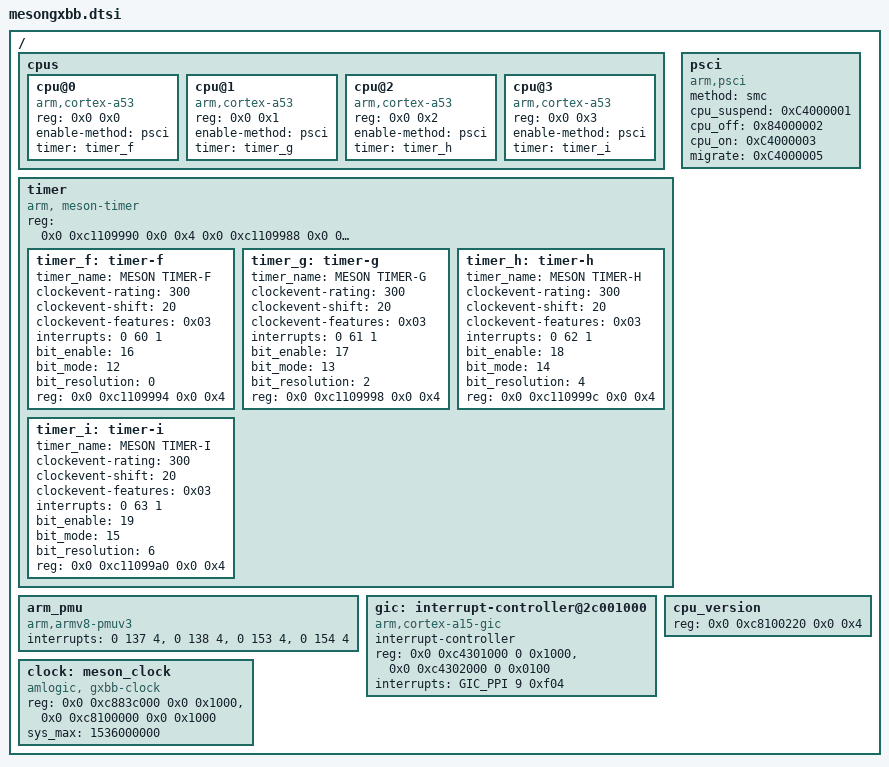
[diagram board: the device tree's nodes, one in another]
#include <dt-bindings/clock/gxbb.h>
/ {
	cpus {
		#address-cells = <2>;
		#size-cells = <0>;

		cpu@0 {
			device_type = "cpu";
			compatible = "arm,cortex-a53","arm,armv8";
			reg = <0x0 0x0>;
			enable-method = "psci";
			timer=<&timer_f>;
		};

		cpu@1 {
			device_type = "cpu";
			compatible = "arm,cortex-a53","arm,armv8";
			reg = <0x0 0x1>;
			enable-method = "psci";
			timer=<&timer_g>;
		};
		cpu@2 {
			device_type = "cpu";
			compatible = "arm,cortex-a53","arm,armv8";
			reg = <0x0 0x2>;
			enable-method = "psci";
			timer=<&timer_h>;
		};

		cpu@3 {
			device_type = "cpu";
			compatible = "arm,cortex-a53","arm,armv8";
			reg = <0x0 0x3>;
			enable-method = "psci";
			timer=<&timer_i>;
		};


	};

	timer{
		compatible = "arm, meson-timer";
		#address-cells = <2>;
		#size-cells = <2>;
		ranges;
		reg=   <0x0 0xc1109990 0x0 0x4 0x0 0xc1109988 0x0 0x4>;
		timer_f:timer-f{
			timer_name="MESON TIMER-F";
			clockevent-rating=<300>;
			clockevent-shift=<20>;
			clockevent-features=<0x03>;
			interrupts = <0 60 1>;
			bit_enable=<16>;
			bit_mode=<12>;
			bit_resolution=<0>;
			reg=   <0x0 0xc1109994 0x0 0x4>;
		};
		timer_g:timer-g{
			timer_name="MESON TIMER-G";
			clockevent-rating=<300>;
			clockevent-shift=<20>;
			clockevent-features=<0x03>;
			interrupts = <0 61 1>;
			bit_enable=<17>;
			bit_mode=<13>;
			bit_resolution=<2>;
			reg=<0x0 0xc1109998 0x0 0x4>;
		};
		timer_h:timer-h{
			timer_name="MESON TIMER-H";
			clockevent-rating=<300>;
			clockevent-shift=<20>;
			clockevent-features=<0x03>;
			interrupts = <0 62 1>;
			bit_enable=<18>;
			bit_mode=<14>;
			bit_resolution=<4>;
			reg=<0x0 0xc110999c 0x0 0x4>;
		};
		timer_i:timer-i{
			timer_name="MESON TIMER-I";
			clockevent-rating=<300>;
			clockevent-shift=<20>;
			clockevent-features=<0x03>;
			interrupts = <0 63 1>;
			bit_enable=<19>;
			bit_mode=<15>;
			bit_resolution=<6>;
			reg=<0x0 0xc11099a0 0x0 0x4>;
		};
	};
	arm_pmu {
		compatible = "arm,armv8-pmuv3";
		interrupts = <0 137 4>,
			     <0 138 4>,
			     <0 153 4>,
			     <0 154 4>;
	};

	gic: interrupt-controller@2c001000 {
		compatible = "arm,cortex-a15-gic", "arm,cortex-a9-gic";
		#interrupt-cells = <3>;
		#address-cells = <0>;
		interrupt-controller;
		reg = <0x0 0xc4301000 0 0x1000>,
		      <0x0 0xc4302000 0 0x0100>;
		interrupts = <GIC_PPI 9 0xf04>;
	};

	psci {
		compatible = "arm,psci";
		method = "smc";
		cpu_suspend = <0xC4000001>;
		cpu_off = <0x84000002>;
		cpu_on = <0xC4000003>;
		migrate = <0xC4000005>;
	};

	clock: meson_clock {
		compatible = "amlogic, gxbb-clock";
		reg = <0x0 0xc883c000 0x0 0x1000>,   /* HIU BUS*/
		          <0x0 0xc8100000 0x0 0x1000>;   //AOBUS
		#clock-cells = <1>;
		#reset-cells = <1>;
		sys_max = <1536000000>;
	};

	cpu_version{
		reg=<0x0 0xc8100220 0x0 0x4>;
	};
};
